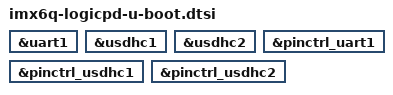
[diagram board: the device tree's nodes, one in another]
// SPDX-License-Identifier: GPL-2.0+
/*
 * Copyright (C) 2019 Logic PD <aford173@gmail.com>
 */

#include "imx6qdl-u-boot.dtsi"

&uart1 {
	u-boot,dm-spl;
};

&usdhc1 {
	u-boot,dm-spl;
};

&usdhc2 {
	u-boot,dm-spl;
};

&pinctrl_uart1 {
	u-boot,dm-spl;
};

&pinctrl_usdhc1 {
	u-boot,dm-spl;
};

&pinctrl_usdhc2 {
	u-boot,dm-spl;
};
